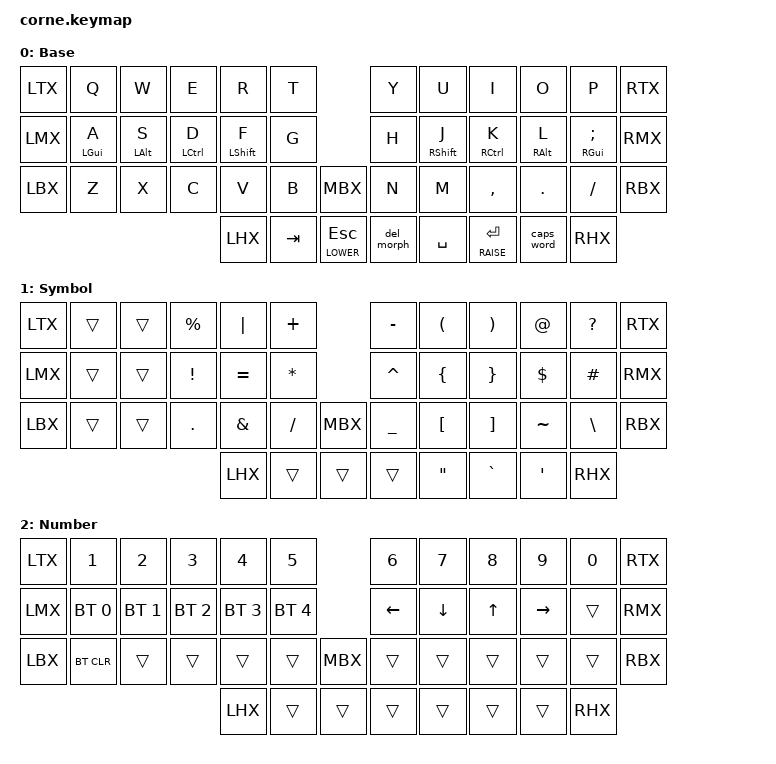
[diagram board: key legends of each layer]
#include <behaviors.dtsi>
#include <dt-bindings/zmk/keys.h>
#include <dt-bindings/zmk/bt.h>
#include <dt-bindings/zmk/ext_power.h>

#define LOWER 1
#define RAISE 2

#include "keys/36.h"

/ {
    chosen {
        zmk,matrix_transform = &five_column_transform;
    };
};

#include "keys/base.h"
#include "includes/mods.dtsi"
#include "includes/morphs.dtsi"
#include "includes/settings.dtsi"

/ {
        keymap {
                compatible = "zmk,keymap";
                default_layer {
                  label = "Base";
// +--------+--------+---------+----------+-------+-----+----------+---------+--------+--------+
// |    q   |    w   |    e    |     r    |   t   |  y  |     u    |    i    |    o   |    p   |
// +--------+--------+---------+----------+-------+-----+----------+---------+--------+--------+
// | a/lgui | s/lalt | d/lctrl | f/lshift |   g   |  h  | j/rshift | k/rctrl | l/ralt | ;/rgui |
// +--------+--------+---------+----------+-------+-----+----------+---------+--------+--------+
// |    z   |    x   |    c    |     v    |   b   |  n  |     m    |    ,    |    .   |    /   |
// +--------+--------+---------+----------+-------+-----+----------+---------+--------+--------+
// |        |        |   tab   |   esc/1  | bkspc | spc |   ent/2  |   caps  |        |        |
// +--------+--------+---------+----------+-------+-----+----------+---------+--------+--------+

                        bindings = <
   _LTX &kp Q        &kp W       &kp E        &kp R         &kp T               &kp Y &kp U          &kp I        &kp O        &kp P           _RTX
   _LMX &hml LGUI A  &hml LALT S &hml LCTRL D &hml LSHIFT F &kp G               &kp H &hmr RSHIFT J  &hmr RCTRL K &hmr RALT L  &hmr RGUI SEMI  _RMX
   _LBX &kp Z        &kp X       &kp C        &kp V         &kp B      _MBX     &kp N &kp M          &kp COMMA    &kp DOT      &kp FSLH        _RBX
                                        _LHX  &kp TAB &lt LOWER ESC &del_morph   &kp SPACE &lt RAISE RET &caps_word _RHX
                        >;
                };

                lower_layer {
                  label = "Symbol";
// +--+--+---+---+---+---+---+---+---+---+
// |  |  | % | | | + | - | ( | ) | @ | ? |
// +--+--+---+---+---+---+---+---+---+---+
// |  |  | ! | = | * | ^ | { | } | $ | # |
// +--+--+---+---+---+---+---+---+---+---+
// |  |  | . | & | / | _ | [ | ] | ~ | \ |
// +--+--+---+---+---+---+---+---+---+---+
// |  |  |   |   |   | " | ` | ' |   |   |
// +--+--+---+---+---+---+---+---+---+---+
                  bindings = <
                    _LTX &trans &trans &kp PRCNT &kp PIPE &kp PLUS           &kp MINUS &kp LPAR  &kp RPAR &kp AT    &kp QMARK  _RTX
                    _LMX &trans &trans &kp EXCL &kp EQUAL &kp STAR           &kp CARET &kp LBRC  &kp RBRC &kp DLLR  &kp HASH   _RMX
                    _LBX &trans &trans &kp DOT &kp AMPS   &kp FSLH   _MBX    &kp UNDER &kp LBKT  &kp RBKT &kp TILDE &kp BSLH   _RBX
                    _LHX               &trans  &trans     &trans             &kp DQT   &kp GRAVE &kp SQT                       _RHX
                    >;
                };

                raise_layer {
                  label = "Number";
// -----------------------------------------------------------------------------------------
// |  1  |  2  |  3  |  4  |  5  |   |  6  |  7  |  8  |  9  |  0  |
// | BT1 | BT2 | BT3 | BT4 | BT5 |   | LFT | DWN |  UP | RGT |     |
// |     |     |     |     |     |   |     |     |     |     |     |
//             | GUI |     | SPC |   | ENT |     | ALT |

                  bindings = <
                      _LTX &kp N1       &kp N2       &kp N3       &kp N4       &kp N5                      &kp N6     &kp N7     &kp N8     &kp N9     &kp N0 _RTX
                      _LMX &bt BT_SEL 0 &bt BT_SEL 1 &bt BT_SEL 2 &bt BT_SEL 3 &bt BT_SEL 4                &kp LEFT   &kp DOWN   &kp UP     &kp RIGHT  &trans _RMX
                      _LBX &bt BT_CLR   &trans       &trans       &trans       &trans          _MBX        &trans     &trans     &trans     &trans     &trans _RBX
                      _LHX                           &trans       &trans       &trans                      &trans     &trans     &trans                       _RHX
                      >;
                };
        };
};
